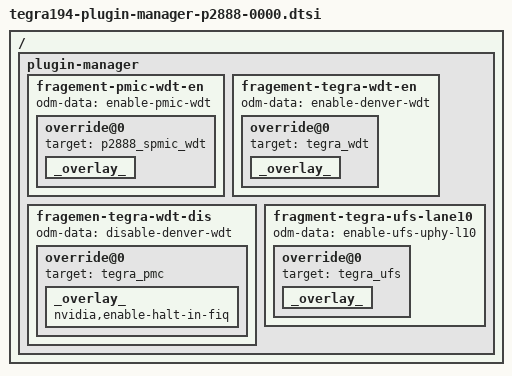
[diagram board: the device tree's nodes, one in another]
/*
 * Copyright (c) 2018, NVIDIA CORPORATION.  All rights reserved.
 *
 * This program is free software; you can redistribute it and/or modify
 * it under the terms of the GNU General Public License as published by
 * the Free Software Foundation; either version 2 of the License, or
 * (at your option) any later version.
 *
 * This program is distributed in the hope that it will be useful, but WITHOUT
 * ANY WARRANTY; without even the implied warranty of MERCHANTABILITY or
 * FITNESS FOR A PARTICULAR PURPOSE.  See the GNU General Public License for
 * more details.
 */

#include "tegra194-p2888-p2822-pcie-plugin-manager.dtsi"

/ {
	plugin-manager {
		fragement-pmic-wdt-en {
			odm-data = "enable-pmic-wdt";
			override@0 {
				target = <&p2888_spmic_wdt>;
				_overlay_ {
					status = "okay";
				};
			};
		};

		fragement-tegra-wdt-en {
			odm-data = "enable-denver-wdt";
			override@0 {
				target = <&tegra_wdt>;
				_overlay_ {
					status = "okay";
				};
			};
		};

		fragemen-tegra-wdt-dis {
			odm-data = "disable-denver-wdt";
			override@0 {
				target = <&tegra_pmc>;
				_overlay_ {
					nvidia,enable-halt-in-fiq;
				};
			};
		};

		fragment-tegra-ufs-lane10 {
			odm-data = "enable-ufs-uphy-l10";
			override@0 {
				target = <&tegra_ufs>;
				_overlay_ {
					status = "okay";
				};
			};
		};
	};
};
